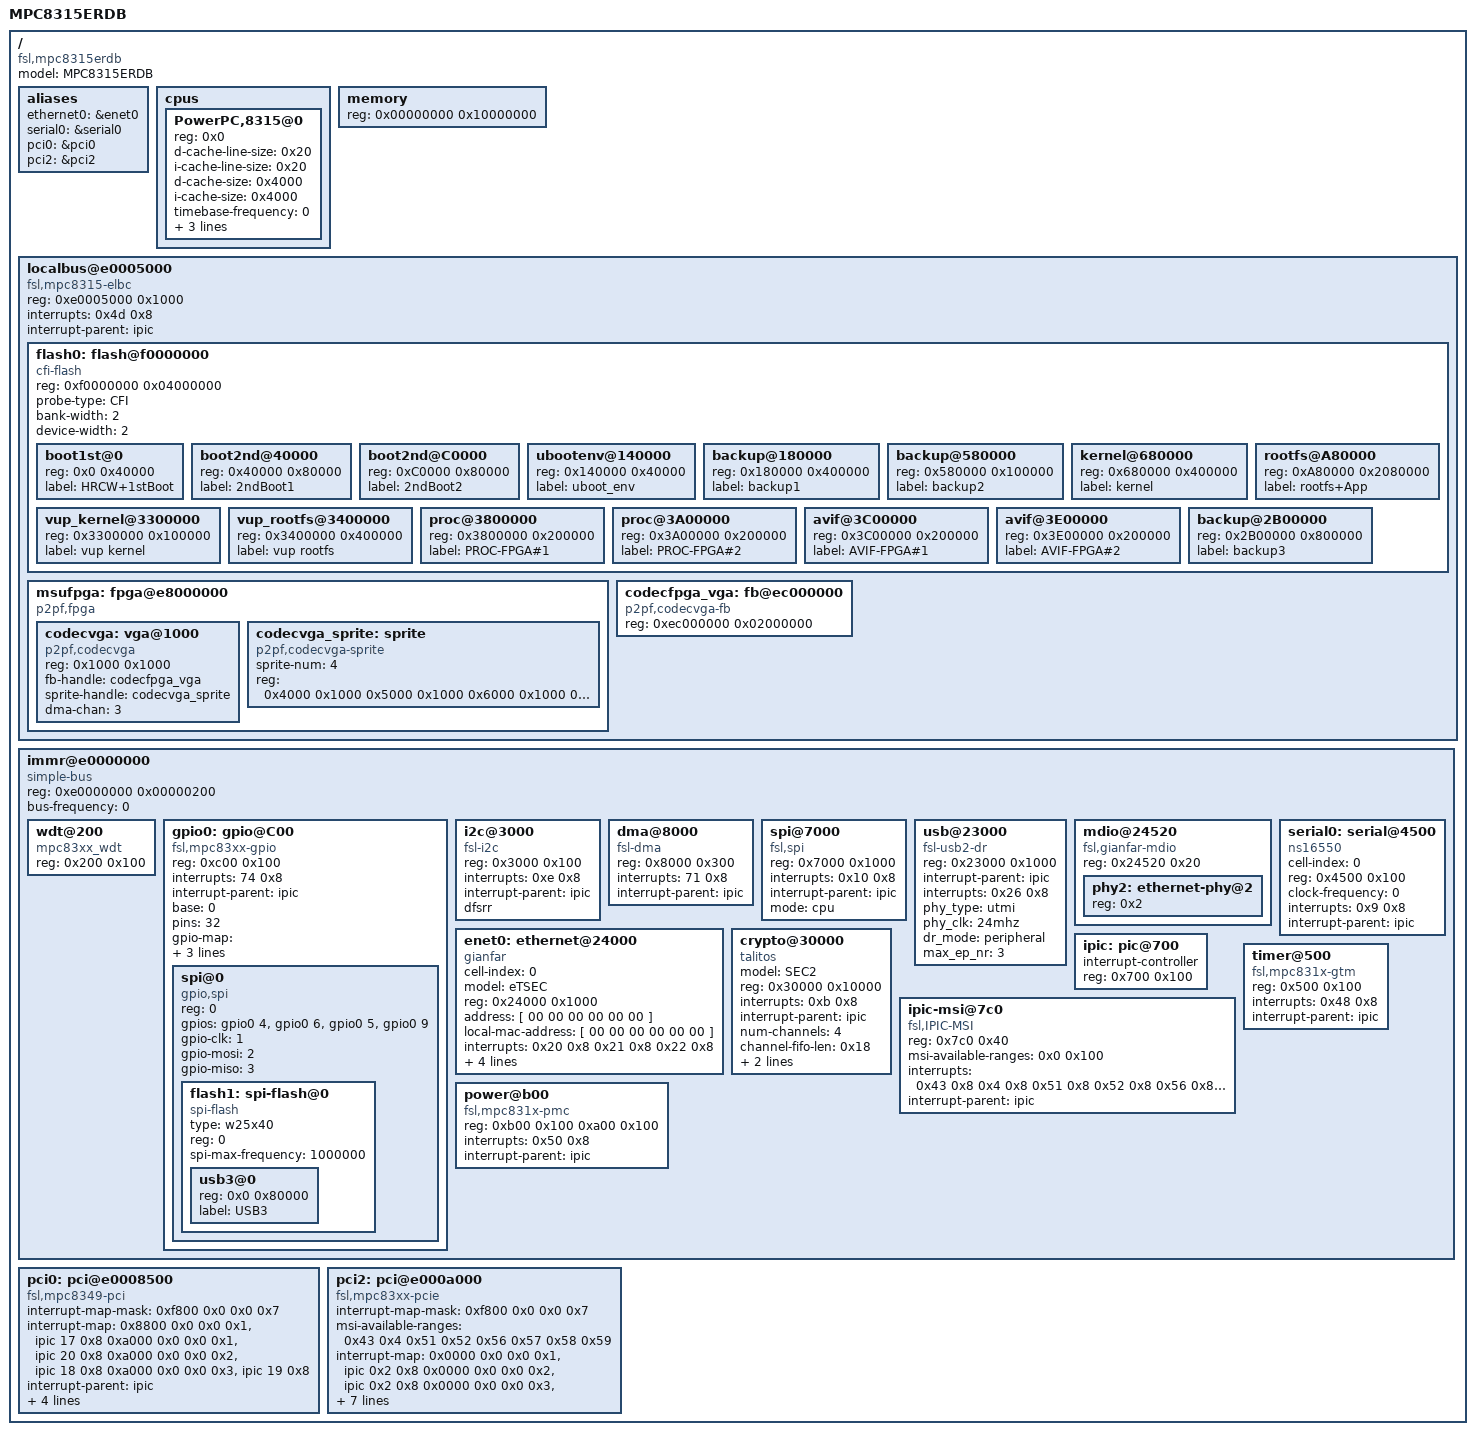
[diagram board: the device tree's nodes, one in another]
/*
 * MPC8315E RDB Device Tree Source
 *
 * Copyright (C) 2007-2008 Freescale Semiconductor Inc. All rights reserved.
 *
 * This program is free software; you can redistribute it and/or modify it
 * under the terms of the GNU General Public License as published by the
 * Free Software Foundation; either version 2 of the License, or (at your
 * option) any later version.
 */
/* $Id: K302_0_default.dts 11740 2011-01-17 07:25:21Z Noguchi Isao $ */

/dts-v1/;

/ {
	model = "MPC8315ERDB";
	compatible = "fsl,mpc8315erdb", "MPC831xRDB", "MPC83xxRDB";
	#address-cells = <1>;
	#size-cells = <1>;

	aliases {
		ethernet0 = &enet0;
		/* ethernet1 = &enet1; */
		serial0 = &serial0;
		/* serial1 = &serial1; */
		pci0 = &pci0;
//		pci1 = &pci1;
		pci2 = &pci2;
	};

	cpus {
		#address-cells = <1>;
		#size-cells = <0>;

		PowerPC,8315@0 {
			device_type = "cpu";
			reg = <0x0>;
			d-cache-line-size = <0x20>;	// 32 bytes
			i-cache-line-size = <0x20>;	// 32 bytes
			d-cache-size = <0x4000>;		// L1, 16K
			i-cache-size = <0x4000>;		// L1, 16K
			timebase-frequency = <0>;	// from bootloader
			bus-frequency = <0>;		// from bootloader
			clock-frequency = <0>;		// from bootloader
			32-bit;
		};
	};

	memory {
		device_type = "memory";
		reg = <0x00000000 0x10000000>;	// 256MB at 0
	};

	localbus@e0005000 {
		#address-cells = <1>;
		#size-cells = <1>;
		compatible = "fsl,mpc8315-elbc",
					"fsl,elbc", "simple-bus";
		reg = <0xe0005000 0x1000>;
		interrupts = <0x4d 0x8>;
		interrupt-parent = < &ipic >;

		flash0: flash@f0000000 {
			#address-cells = <1>;
			#size-cells = <1>;
			device_type = "rom";
			compatible = "cfi-flash";
			ranges = <0x0 0xf0000000 0x04000000>;
			reg = <0xf0000000 0x04000000>; /* CS0: 64MB */
			probe-type = "CFI";
			bank-width = <2>;
			device-width = <2>;
            boot1st@0 {
                reg = <0x0 0x40000>;
                label = "HRCW+1stBoot";
            };
            boot2nd@40000 {
                reg = <0x40000 0x80000>;
				label = "2ndBoot1";
            };
            boot2nd@C0000 {
                reg = <0xC0000 0x80000>;
				label = "2ndBoot2";
            };
            ubootenv@140000 {
                reg = <0x140000 0x40000>;
				label = "uboot_env";
            };
            backup@180000 {
                reg = <0x180000 0x400000>;
                label = "backup1";
            };
            backup@580000 {
                reg = <0x580000 0x100000>;
                label = "backup2";
            };
            kernel@680000 {
                reg = <0x680000 0x400000>;
                label = "kernel";
            };
            rootfs@A80000 {
                reg = <0xA80000 0x2080000>;
                label = "rootfs+App";
            };
            vup_kernel@3300000 {
                reg = <0x3300000 0x100000>;
                label = "vup kernel";
            };
            vup_rootfs@3400000 {
                reg = <0x3400000 0x400000>;
                label = "vup rootfs";
            };
            proc@3800000 {
                reg = <0x3800000 0x200000>;
                label = "PROC-FPGA#1";
            };
            proc@3A00000 {
                reg = <0x3A00000 0x200000>;
                label = "PROC-FPGA#2";
            };
            avif@3C00000 {
                reg = <0x3C00000 0x200000>;
                label = "AVIF-FPGA#1";
            };
            avif@3E00000 {
                reg = <0x3E00000 0x200000>;
                label = "AVIF-FPGA#2";
            };
            backup@2B00000 {
                reg = <0x2B00000 0x800000>;
                label = "backup3";
            };
		};

        msufpga: fpga@e8000000 {
			#address-cells = <1>;
			#size-cells = <1>;
			device_type = "fpga";
			compatible = "p2pf,fpga","p2pf,msudev-fpga";
			ranges = <0x0 0xe8000000 0x8000>; // CS2

            codecvga: vga@1000 {
            	device_type = "display";
	            compatible = "p2pf,codecvga","p2pf,msudev-codecvga";
                reg = <0x1000 0x1000>;
                fb-handle = <&codecfpga_vga>;
                sprite-handle = <&codecvga_sprite>;
                dma-chan = <3>;
            };

            codecvga_sprite: sprite {
                compatible = "p2pf,codecvga-sprite";
                sprite-num = <4>;
                reg = < 0x4000 0x1000
                        0x5000 0x1000
                        0x6000 0x1000
                        0x7000 0x1000 >;                
            };

        };

        codecfpga_vga: fb@ec000000 {
            compatible = "p2pf,codecvga-fb";
            reg = <0xec000000 0x02000000>;
        };

	};

	immr@e0000000 {
		#address-cells = <1>;
		#size-cells = <1>;
		#interrupt-cells = <2>;
		device_type = "soc";
		compatible = "simple-bus","fsl,mpc8315-immr";
		ranges = <0x0 0xe0000000 0x00100000>;
		reg = <0xe0000000 0x00000200>;
		bus-frequency = <0>;

		wdt@200 {
			device_type = "watchdog";
			compatible = "mpc83xx_wdt";
			reg = <0x200 0x100>;
		};

        gpio0: gpio@C00 {
			#gpio-cells = <2>;
            device_type = "gpio";
			compatible = "fsl,mpc83xx-gpio";
			reg = <0xc00 0x100>;
			interrupts = <74 0x8>;
			interrupt-parent = <&ipic>;
			base = <0>;          /* Added by Panasonic */
            pins = <32>;          /* Added by Panasonic */
            gpio-map = <          /* Added by Panasonic */
            /*
             *  *** register setting  ***
             *  pin : pin number
             *  dir : dirction (0:IN, 1:OUT)
             *  odr : open drain output (0:disable, 1:enable)
             *  dat : data latch value (0:'L', 1:'H')
             *  icr : IRQ control (0:any change trigger, 1: down edge only)
             */
            /* pin dir odr dat icr */
                0   0   0   1   0       // dipsw[4]
                1   0   0   1   0       // dipsw[3]
                2   0   0   1   0       // dipsw[2]
                3   0   0   1   0       // dipsw[1]
                4   1   0   0   0       // USB3_SPI_CS_N/LED[0]
                5   1   0   0   0       // USB3_SPI_DOUT/LED[1]
                6   1   0   0   0       // USB3_SPI_CLK/LED[2]
                7   1   0   0   0       // LED[3]
                8   1   0   0   0       // VBUS_3D_OFF_N
                9   0   0   1   0       // USB3_SPI_DIN
               10   1   0   0   0       // VBUS_KBD_OFF_N
               11   1   0   0   0       // VBUS_USBDEV_OFF_N
               15   1   0   1   0       // PCIE_SSC_ON (ES1.5 or later)
               16   0   0   1   0       // ZION_RDY_N
               17   1   0   1   0       // SD_LED_N
               18   1   0   0   0       // VBUS_USB3_OFF_N
               19   0   0   1   1       // REF5V_OCI_N
/*
               20   1   0   1   0       // RST_RICOH_N
*/
               21   1   0   1   0       // USB3_SPI_SEL
/*
               22   1   0   1   0       // RST_USB2HUB_N
               23   1   0   1   0       // RST_PCIE_N
               26   1   0   1   0       // RST_SYS_N
               27   1   0   1   0       // SYS_W_N
*/
            >;
            mask-pins = < 24 25 28 29 30 31>;          /* Added by Panasonic */
 			gpio-controller;


            spi@0 {
                #address-cells = <1>;
                #size-cells = <0>;
                device_type = "spi";
    			compatible = "gpio,spi","gpio-spi";
                reg = <0>;
                gpios = <
                    &gpio0 4 0 // USB3_SPI_CS_N is pin 4 of GPIO#0
                    &gpio0 6 0 // USB3_SPI_CLK is pin 6 GPIO#0
                    &gpio0 5 0 // USB3_SPI_DOUT is pin 5 GPIO#0
                    &gpio0 9 0 // USB3_SPI_DIN
                >;
                gpio-clk = <1>; // index of 'gpios' property
                gpio-mosi = <2>; // index of 'gpios' property
                gpio-miso = <3>; // index of 'gpios' property
//                open-drain; // open-drain mode

                // Winbond W25X40 serial flash device with SPI interface
                flash1: spi-flash@0 {
        			#address-cells = <1>;
                    #size-cells = <1>;
                    ranges = <0x0 0x00000 0x80000>;
                    device_type = "rom";
                    compatible = "spi-flash","m25p80","linux,m25p80";
        			type = "w25x40";

                    reg = <0>;  // index of 'gpios' property in parent's node (spi)
//                    spi-cpha;   // clock starts toggling at the beginning of the data transfer
//                    spi-cpol;   // inactive state of clock is high
//                    spi-cspol;  // active state of CS is high
//                    spi-3wire;  // SI/SO signals shared
                spi-max-frequency = <1000000>;  // MAX 1MHz

                    usb3@0 {
                        reg = <0x0 0x80000>;
                        label = "USB3";
                    };

                };
            };

        };

		i2c@3000 {
			#address-cells = <1>;
			#size-cells = <0>;
			device_type = "i2c";
			compatible = "fsl-i2c";
			reg = <0x3000 0x100>;
			interrupts = <0xe 0x8>;
			interrupt-parent = < &ipic >;
			dfsrr;
		};

		dma@8000 {
			device_type = "dma";
			compatible = "fsl-dma";
			reg = <0x8000 0x300>;
			interrupts = <71 0x8>;
			interrupt-parent = < &ipic >;
		};

		spi@7000 {
			#address-cells = <1>;
			#size-cells = <0>;
			device_type = "spi";
			compatible = "fsl,spi","fsl,mpc837x-spi";
			reg = <0x7000 0x1000>;
			interrupts = <0x10 0x8>;
			interrupt-parent = < &ipic >;
			mode = "cpu";
		};

		/* phy type (ULPI, UTMI, UTMI_WIDE, SERIAL) */
		usb@23000 {
			device_type = "usb";
			compatible = "fsl-usb2-dr";
			reg = <0x23000 0x1000>;
			#address-cells = <1>;
			#size-cells = <0>;
			interrupt-parent = < &ipic >;
			interrupts = <0x26 0x8>;
			phy_type = "utmi";          /* Added by Panasonic */
			phy_clk  = "24mhz";         /* Added by Panasonic */
			dr_mode = "peripheral";     /* for DEVICE */
			max_ep_nr = <3>;            /* Added by Panasonic */
		};

		mdio@24520 {
			#address-cells = <1>;
			#size-cells = <0>;
			device_type = "mdio";
			compatible = "fsl,gianfar-mdio";
			reg = <0x24520 0x20>;
			phy2: ethernet-phy@2 {
				reg = <0x2>;
				device_type = "ethernet-phy";
			};
/*
			phy1: ethernet-phy@1 {
				reg = <0x1>;
				device_type = "ethernet-phy";
			};
*/
		};

		enet0: ethernet@24000 {
			cell-index = <0>;
			device_type = "network";
			model = "eTSEC";
			compatible = "gianfar";
			reg = <0x24000 0x1000>;
			address = [ 00 00 00 00 00 00 ];
			local-mac-address = [ 00 00 00 00 00 00 ];
			interrupts = <0x20 0x8 0x21 0x8 0x22 0x8>;
			// phy-connection-type = "mii";
			interrupt-parent = < &ipic >;
			phy-handle = < &phy2 >;
			sleep = <0xb00 0xc0000000>;
			fsl,magic-packet;
		};
/*
		enet1: ethernet@25000 {
			cell-index = <1>;
			device_type = "network";
			model = "eTSEC";
			compatible = "gianfar";
			reg = <0x25000 0x1000>;
			address = [ 00 00 00 00 00 00 ];
			local-mac-address = [ 00 00 00 00 00 00 ];
			interrupts = <0x23 0x8 0x24 0x8 0x25 0x8>;
			// phy-connection-type = "mii";
			interrupt-parent = < &ipic >;
			phy-handle = < &phy1 >;
			sleep = <0xb00 0x30000000>;
			fsl,magic-packet;
		};
*/
		serial0: serial@4500 {
			cell-index = <0>;
			device_type = "serial";
			compatible = "ns16550";
			reg = <0x4500 0x100>;
			clock-frequency = <0>;
			interrupts = <0x9 0x8>;
			interrupt-parent = < &ipic >;
		};
/*
		serial1: serial@4600 {
			cell-index = <1>;
			device_type = "serial";
			compatible = "ns16550";
			reg = <0x4600 0x100>;
			clock-frequency = <0>;
			interrupts = <0xa 0x8>;
			interrupt-parent = < &ipic >;
		};

		serdes@e3000 {
			model = "SerDes";
			compatible = "fsl,serdes";
			reg = <0xe3000 0x100>;
			vdd-1v;
			pex-x1;
			protocol = "pex";
			clock = <100>;
		};

		tdm@16000 {
			device_type = "tdm";
			compatible = "fsl,mpc8315-tdm";
			reg = <0x16000 0x200 0x2c000 0x2000>;
			clock-frequency = <0>;
			interrupts = <0x53 0x8 0x5e 0x8 0x3 0x8>;
			interrupt-parent = < &ipic >;
		};

		legerity {
			device_type="slic";
			compatible = "legerity-slic";
			clock-frequency = <0>;
			interrupts = <0x16 0x8>;
			interrupt-parent = < &ipic >;
		};
*/

		crypto@30000 {
			device_type = "crypto";
			model = "SEC2";
			compatible = "talitos";
			reg = <0x30000 0x10000>;
			interrupts = <0xb 0x8>;
			interrupt-parent = < &ipic >;
			/* Rev. 2.2 */
			num-channels = <4>;
			channel-fifo-len = <0x18>;
			exec-units-mask = <0x0000097c>;
			descriptor-types-mask = <0x03a30abf>;
		};

		/* SATA 1 (eSATA i/f) */
/*
		sata@18000 {
			compatible = "fsl,mpc8315-sata","fsl,pq-sata";
			reg = <0x18000 0x1000>;
			interrupts = <0x2c 0x8>;
			interrupt-parent = < &ipic >;
		};
*/

		/* SATA 2 (internal SSD i/f) */
/*
		sata@19000 {
			compatible = "fsl,mpc8315-sata","fsl,pq-sata";
			reg = <0x19000 0x1000>;
			interrupts = <0x2d 0x8>;
			interrupt-parent = < &ipic >;
		};
*/

		/* IPIC
		 * interrupts cell = <intr #, sense>
		 * sense values match linux IORESOURCE_IRQ_* defines:
		 * sense == 8: Level, low assertion
		 * sense == 2: Edge, high-to-low change
		 */
		ipic: pic@700 {
			interrupt-controller;
			#address-cells = <0>;
			#interrupt-cells = <2>;
			reg = <0x700 0x100>;
			device_type = "ipic";
		};
		ipic-msi@7c0 {
			compatible = "fsl,IPIC-MSI";
			reg = <0x7c0 0x40>;
			msi-available-ranges = <0x0 0x100>;
			interrupts = < 0x43 0x8
				       0x4  0x8
				       0x51 0x8
				       0x52 0x8
				       0x56 0x8
				       0x57 0x8
				       0x58 0x8
				       0x59 0x8 >;
			interrupt-parent = < &ipic >;
		};
		power@b00 {
			linux,phandle = <0xb00>;
			device_type = "power";
			compatible = "fsl,mpc831x-pmc", "fsl,mpc83xx-pmc";
			reg = <0xb00 0x100
				0xa00 0x100>;
			interrupts = <0x50 0x8>;
			interrupt-parent = < &ipic>;
		};

		timer@500 {
			linux,phandle = <0x500>;
			device_type = "timer";
			compatible = "fsl,mpc831x-gtm", "fsl,mpc83xx-gtm";
			reg = <0x500 0x100>;
			interrupts = <0x48 0x8>;
			interrupt-parent = < &ipic>;
		};
	};

	pci0:pci@e0008500 {
		interrupt-map-mask = <0xf800 0x0 0x0 0x7>;
		interrupt-map = <
				/* IDSEL AD17(0x11) : ZION */
                   0x8800 0x0 0x0 0x1 &ipic 17 0x8     /*INTA*/

				/* IDSEL AD20(0x14) : Ricoh */
				   0xa000 0x0 0x0 0x1 &ipic 20 0x8     /*INTD*/
				   0xa000 0x0 0x0 0x2 &ipic 18 0x8     /*INTB*/
				   0xa000 0x0 0x0 0x3 &ipic 19 0x8     /*INTC*/
				>;
		interrupt-parent = < &ipic >;
		interrupts = <0x42 0x8>;
		bus-range = <0x0 0x0>;
		ranges = <
                    0x02000000 0x0 0x90000000 0x90000000 0x0 0x10000000 // MEMIO
                    0x42000000 0x0 0x80000000 0x80000000 0x0 0x10000000 // PREFETCH
                    0x01000000 0x0 0x00000000 0xe0300000 0x0 0x00100000 // IO
                >;
		clock-frequency = <0>;
		#interrupt-cells = <1>;
		#size-cells = <2>;
		#address-cells = <3>;
		//reg = <0xe0008500 0x100>;
		reg = <
                0xe0008500 0x100    // PCI controller
                0xe0008300 0x80     // PCI configuration access
                >;
		compatible = "fsl,mpc8349-pci";
		device_type = "pci";
	};
/*
	pci1: pci@e0009000 { // Added by Panasonic
		interrupt-map-mask = <0xf800 0x0 0x0 0x7>;
		msi-available-ranges = <0x43 0x4 0x51 0x52 0x56 0x57 0x58 0x59>;
		interrupt-map = <
			0x0000 0x0 0x0 0x1 &ipic 0x1 0x8
			0x0000 0x0 0x0 0x2 &ipic 0x1 0x8
			0x0000 0x0 0x0 0x3 &ipic 0x1 0x8
			0x0000 0x0 0x0 0x4 &ipic 0x1 0x8>;
		interrupt-parent = < &ipic >;
		interrupts = <0x1 0x8>;
		bus-range = <0x0 0x0>;
		ranges = <
                    0x02000000 0x0 0xA8000000 0xA8000000 0x0 0x10000000 // MEMIO
                    0x01000000 0x0 0x00800000 0xB8000000 0x0 0x00400000 // IO
                >;
		clock-frequency = <0>;
		#interrupt-cells = <1>;
		#size-cells = <2>;
		#address-cells = <3>;
//		reg = <0xe0009000 0x1000>;
		reg = <
                0xe0009000 0x1000       // PCIe controller
                0xa0000000 0x08000000   // CFG area space
        >;
		compatible = "fsl,mpc83xx-pcie", "fsl,mpc8315-pcie";
//		compatible = "fsl,mpc8349-pci";
		device_type = "pci";
	};
*/
	pci2: pci@e000a000 { // Added by Panasonic
		interrupt-map-mask = <0xf800 0x0 0x0 0x7>;
		msi-available-ranges = <0x43 0x4 0x51 0x52 0x56 0x57 0x58 0x59>;
		interrupt-map = <
			0x0000 0x0 0x0 0x1 &ipic 0x2 0x8
			0x0000 0x0 0x0 0x2 &ipic 0x2 0x8
			0x0000 0x0 0x0 0x3 &ipic 0x2 0x8
			0x0000 0x0 0x0 0x4 &ipic 0x2 0x8>;
		interrupt-parent = < &ipic >;
		interrupts = <0x2 0x8>;
		bus-range = <0x0 0x0>;
		ranges = <
                    0x02000000 0x0 0xC8000000 0xC8000000 0x0 0x10000000 // MEMIO
                    0x01000000 0x0 0x00C00000 0xD8000000 0x0 0x00400000 // IO
                >;
		clock-frequency = <0>;
		#interrupt-cells = <1>;
		#size-cells = <2>;
		#address-cells = <3>;
//		reg = <0xe000a000 0x1000>;
		reg = <
               0xe000a000 0x1000        // PCIe controller
               0xc0000000 0x08000000    // CFG area space
        >;
		compatible = "fsl,mpc83xx-pcie", "fsl,mpc8315-pcie";
//		compatible = "fsl,mpc8349-pci";
		device_type = "pci";
	};
};
